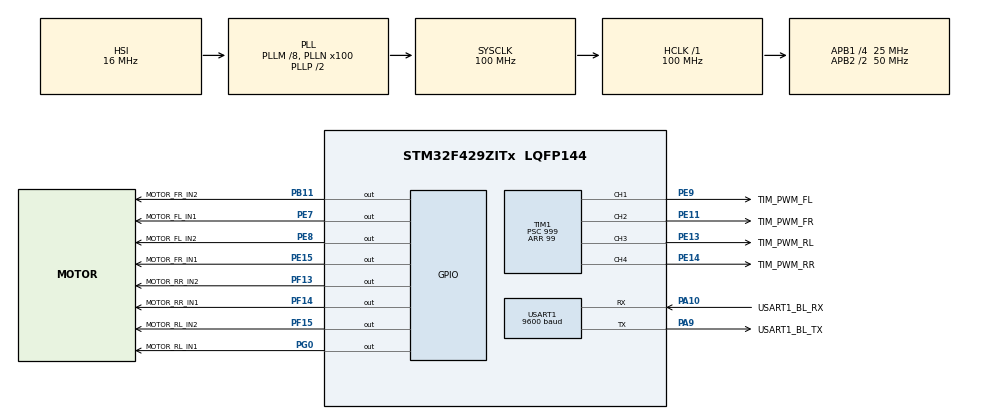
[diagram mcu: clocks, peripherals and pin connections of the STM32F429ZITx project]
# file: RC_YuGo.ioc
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Mcu.Family=STM32F4
Mcu.Name=STM32F429ZITx
Mcu.Package=LQFP144
NVIC.PriorityGroup=NVIC_PRIORITYGROUP_4
NVIC.TIM3_IRQn=true\:0\:0\:false\:false\:true\:true\:true\:true
NVIC.TIM4_IRQn=true\:0\:0\:false\:false\:true\:true\:true\:true
NVIC.USART1_IRQn=true\:0\:0\:false\:false\:true\:true\:true\:true
PA10.GPIO_Label=USART1_BL_RX
PA10.Mode=Asynchronous
PA10.Signal=USART1_RX
PA9.GPIO_Label=USART1_BL_TX
PA9.Mode=Asynchronous
PA9.Signal=USART1_TX
PB11.GPIO_Label=MOTOR_FR_IN2
PB11.GPIO_Speed=GPIO_SPEED_FREQ_MEDIUM
PB11.Signal=GPIO_Output
PC14/OSC32_IN.Mode=LSE-External-Oscillator
PC14/OSC32_IN.Signal=RCC_OSC32_IN
PC15/OSC32_OUT.Mode=LSE-External-Oscillator
PC15/OSC32_OUT.Signal=RCC_OSC32_OUT
PE11.GPIO_Label=TIM_PWM_FR
PE11.Signal=S_TIM1_CH2
PE13.GPIO_Label=TIM_PWM_RL
PE13.Signal=S_TIM1_CH3
PE14.GPIO_Label=TIM_PWM_RR
PE14.Signal=S_TIM1_CH4
PE15.GPIO_Label=MOTOR_FR_IN1
PE15.GPIO_Speed=GPIO_SPEED_FREQ_MEDIUM
PE15.Signal=GPIO_Output
PE7.GPIO_Label=MOTOR_FL_IN1
PE7.GPIO_Speed=GPIO_SPEED_FREQ_MEDIUM
PE7.Signal=GPIO_Output
PE8.GPIO_Label=MOTOR_FL_IN2
PE8.GPIO_Speed=GPIO_SPEED_FREQ_MEDIUM
PE8.Signal=GPIO_Output
PE9.GPIO_Label=TIM_PWM_FL
PE9.Signal=S_TIM1_CH1
PF13.GPIO_Label=MOTOR_RR_IN2
PF13.GPIO_Speed=GPIO_SPEED_FREQ_MEDIUM
PF13.Signal=GPIO_Output
PF14.GPIO_Label=MOTOR_RR_IN1
PF14.GPIO_Speed=GPIO_SPEED_FREQ_MEDIUM
PF14.Signal=GPIO_Output
PF15.GPIO_Label=MOTOR_RL_IN2
PF15.GPIO_Speed=GPIO_SPEED_FREQ_MEDIUM
PF15.Signal=GPIO_Output
PG0.GPIO_Label=MOTOR_RL_IN1
PG0.GPIO_Speed=GPIO_SPEED_FREQ_MEDIUM
PG0.Signal=GPIO_Output
PH0/OSC_IN.Mode=HSE-External-Oscillator
PH0/OSC_IN.Signal=RCC_OSC_IN
PH1/OSC_OUT.Mode=HSE-External-Oscillator
PH1/OSC_OUT.Signal=RCC_OSC_OUT
ProjectManager.HeapSize=0x200
ProjectManager.StackSize=0x400
ProjectManager.TargetToolchain=STM32CubeIDE
RCC.48MHZClocksFreq_Value=50000000
RCC.AHBFreq_Value=100000000
RCC.APB1CLKDivider=RCC_HCLK_DIV4
RCC.APB1Freq_Value=25000000
RCC.APB1TimFreq_Value=50000000
RCC.APB2CLKDivider=RCC_HCLK_DIV2
RCC.APB2Freq_Value=50000000
RCC.APB2TimFreq_Value=100000000
RCC.CortexFreq_Value=100000000
RCC.HCLKFreq_Value=100000000
RCC.HSE_VALUE=25000000
RCC.HSI_VALUE=16000000
RCC.PLLM=8
RCC.PLLN=100
RCC.SYSCLKFreq_VALUE=100000000
RCC.SYSCLKSource=RCC_SYSCLKSOURCE_PLLCLK
RCC.VCOOutputFreq_Value=200000000
SH.S_TIM1_CH1.0=TIM1_CH1,PWM Generation1 CH1
SH.S_TIM1_CH2.0=TIM1_CH2,PWM Generation2 CH2
SH.S_TIM1_CH3.0=TIM1_CH3,PWM Generation3 CH3
SH.S_TIM1_CH4.0=TIM1_CH4,PWM Generation4 CH4
TIM1.AutoReloadPreload=TIM_AUTORELOAD_PRELOAD_DISABLE
TIM1.Channel-PWM\ Generation1\ CH1=TIM_CHANNEL_1
TIM1.Channel-PWM\ Generation2\ CH2=TIM_CHANNEL_2
TIM1.Channel-PWM\ Generation3\ CH3=TIM_CHANNEL_3
TIM1.Channel-PWM\ Generation4\ CH4=TIM_CHANNEL_4
TIM1.Period=99
TIM1.Prescaler=999
TIM3.Period=499
TIM3.Prescaler=4999
TIM4.Period=9999
TIM4.Prescaler=4999
USART1.BaudRate=9600
USART1.VirtualMode=VM_ASYNC
VP_TIM1_VS_ClockSourceINT.Mode=Internal
VP_TIM3_VS_ClockSourceINT.Mode=Internal
VP_TIM4_VS_ClockSourceINT.Mode=Internal
board=custom

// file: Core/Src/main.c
/* USER CODE BEGIN Header */
/**
  ******************************************************************************
  * @file           : main.c
  * @brief          : Main program body
  ******************************************************************************
  * @attention
  *
  * Copyright (c) 2023 STMicroelectronics.
  * All rights reserved.
  *
  * This software is licensed under terms that can be found in the LICENSE file
  * in the root directory of this software component.
  * If no LICENSE file comes with this software, it is provided AS-IS.
  *
  ******************************************************************************
  */
/* USER CODE END Header */
#include "main.h"
#include "tim.h"
#include "usart.h"
#include "gpio.h"

/* USER CODE BEGIN Includes */
#include <stdbool.h>
#include "motor.h"
#include "receiver.h"
#include "joystick_utility.h"
#include "actions_controller.h"
#include "motor_controller.h"
/* USER CODE END Includes */

void SystemClock_Config(void);

int main(void)
{

  /* MCU Configuration--------------------------------------------------------*/

  /* Reset of all peripherals, Initializes the Flash interface and the Systick. */
  HAL_Init();

  /* Configure the system clock */
  SystemClock_Config();

  /* Initialize all configured peripherals */
  MX_GPIO_Init();
  MX_TIM1_Init();
  MX_USART1_UART_Init();
  MX_TIM3_Init();
  MX_TIM4_Init();
  /* USER CODE BEGIN 2 */
  intializeMotors();

  Receiver_initialize(&huart1);
  Receiver_addAction('j', joystickAction);

  // Bluetooth period timer
  HAL_TIM_Base_Start_IT(&htim4);
  /* USER CODE END 2 */

  /* Infinite loop */
  while (1)
  {

  }
}

void SystemClock_Config(void)
{
  RCC_OscInitTypeDef RCC_OscInitStruct = {0};
  RCC_ClkInitTypeDef RCC_ClkInitStruct = {0};

  /** Configure the main internal regulator output voltage
  */
  __HAL_RCC_PWR_CLK_ENABLE();
  __HAL_PWR_VOLTAGESCALING_CONFIG(PWR_REGULATOR_VOLTAGE_SCALE3);

  /** Initializes the RCC Oscillators according to the specified parameters
  * in the RCC_OscInitTypeDef structure.
  */
  RCC_OscInitStruct.OscillatorType = RCC_OSCILLATORTYPE_HSI;
  RCC_OscInitStruct.HSIState = RCC_HSI_ON;
  RCC_OscInitStruct.HSICalibrationValue = RCC_HSICALIBRATION_DEFAULT;
  RCC_OscInitStruct.PLL.PLLState = RCC_PLL_ON;
  RCC_OscInitStruct.PLL.PLLSource = RCC_PLLSOURCE_HSI;
  RCC_OscInitStruct.PLL.PLLM = 8;
  RCC_OscInitStruct.PLL.PLLN = 100;
  RCC_OscInitStruct.PLL.PLLP = RCC_PLLP_DIV2;
  RCC_OscInitStruct.PLL.PLLQ = 4;
  if (HAL_RCC_OscConfig(&RCC_OscInitStruct) != HAL_OK)
  {
    Error_Handler();
  }

  /** Initializes the CPU, AHB and APB buses clocks
  */
  RCC_ClkInitStruct.ClockType = RCC_CLOCKTYPE_HCLK|RCC_CLOCKTYPE_SYSCLK
                              |RCC_CLOCKTYPE_PCLK1|RCC_CLOCKTYPE_PCLK2;
  RCC_ClkInitStruct.SYSCLKSource = RCC_SYSCLKSOURCE_PLLCLK;
  RCC_ClkInitStruct.AHBCLKDivider = RCC_SYSCLK_DIV1;
  RCC_ClkInitStruct.APB1CLKDivider = RCC_HCLK_DIV4;
  RCC_ClkInitStruct.APB2CLKDivider = RCC_HCLK_DIV2;

  if (HAL_RCC_ClockConfig(&RCC_ClkInitStruct, FLASH_LATENCY_3) != HAL_OK)
  {
    Error_Handler();
  }
}

void Error_Handler(void)
{
  __disable_irq();
  while (1)
  {
  }
}
